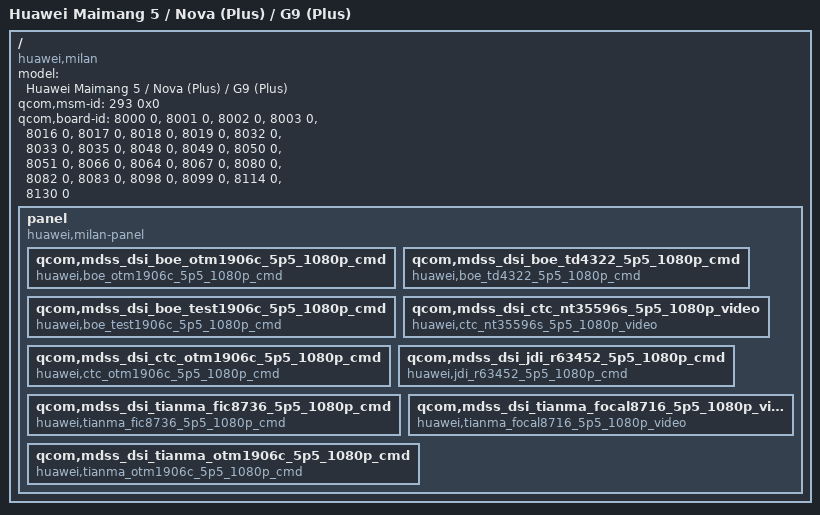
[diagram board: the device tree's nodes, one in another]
// SPDX-License-Identifier: GPL-2.0-only
// Copyright (c) 2023, bzy-080408 <Bzy080408@outlook.com>

/dts-v1/;

/include/ "msm8953.dtsi"

/ {
	model = "Huawei Maimang 5 / Nova (Plus) / G9 (Plus)";
	compatible = "huawei,milan", "qcom,msm8953", "lk2nd,device";
	qcom,msm-id = <293 0x0>;
	qcom,board-id = <8000 0>, <8001 0>, <8002 0>, <8003 0>, <8016 0>,
			<8017 0>, <8018 0>, <8019 0>, <8032 0>, <8033 0>,
			<8035 0>, <8048 0>, <8049 0>, <8050 0>, <8051 0>,
			<8066 0>, <8064 0>, <8067 0>, <8080 0>, <8082 0>,
			<8083 0>, <8098 0>, <8099 0>, <8114 0>, <8130 0>;

	panel {
		compatible = "huawei,milan-panel";

		qcom,mdss_dsi_boe_otm1906c_5p5_1080p_cmd {
			compatible = "huawei,boe_otm1906c_5p5_1080p_cmd";
		};
		qcom,mdss_dsi_boe_td4322_5p5_1080p_cmd {
			compatible = "huawei,boe_td4322_5p5_1080p_cmd";
		};
		qcom,mdss_dsi_boe_test1906c_5p5_1080p_cmd {
			compatible = "huawei,boe_test1906c_5p5_1080p_cmd";
		};
		qcom,mdss_dsi_ctc_nt35596s_5p5_1080p_video {
			compatible = "huawei,ctc_nt35596s_5p5_1080p_video";
		};
		qcom,mdss_dsi_ctc_otm1906c_5p5_1080p_cmd {
			compatible = "huawei,ctc_otm1906c_5p5_1080p_cmd";
		};
		qcom,mdss_dsi_jdi_r63452_5p5_1080p_cmd {
			compatible = "huawei,jdi_r63452_5p5_1080p_cmd";
		};
		qcom,mdss_dsi_tianma_fic8736_5p5_1080p_cmd {
			compatible = "huawei,tianma_fic8736_5p5_1080p_cmd";
		};
		qcom,mdss_dsi_tianma_focal8716_5p5_1080p_video {
			compatible = "huawei,tianma_focal8716_5p5_1080p_video";
		};
		qcom,mdss_dsi_tianma_otm1906c_5p5_1080p_cmd {
			compatible = "huawei,tianma_otm1906c_5p5_1080p_cmd";
		};
	};
};
